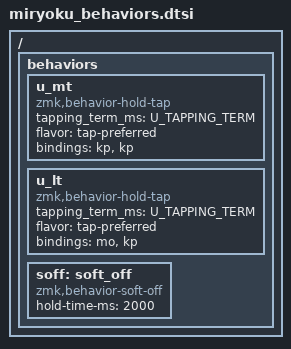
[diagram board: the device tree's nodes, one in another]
// Copyright 2022 Manna Harbour
// https://github.com/manna-harbour/miryoku

/ {
  behaviors {
    u_mt: u_mt {
      compatible = "zmk,behavior-hold-tap";
      #binding-cells = <2>;
      tapping_term_ms = <U_TAPPING_TERM>;
      flavor = "tap-preferred";
      bindings = <&kp>, <&kp>;
    };
    u_lt: u_lt {
      compatible = "zmk,behavior-hold-tap";
      #binding-cells = <2>;
      tapping_term_ms = <U_TAPPING_TERM>;
      flavor = "tap-preferred";
      bindings = <&mo>, <&kp>;
    };
    soff: soft_off {
        compatible = "zmk,behavior-soft-off";
        #binding-cells = <0>;
        // split-peripheral-off-on-press;
        hold-time-ms = <2000>; // Only turn off it the key is held for 2 seconds or longer.
    };
  };
};
